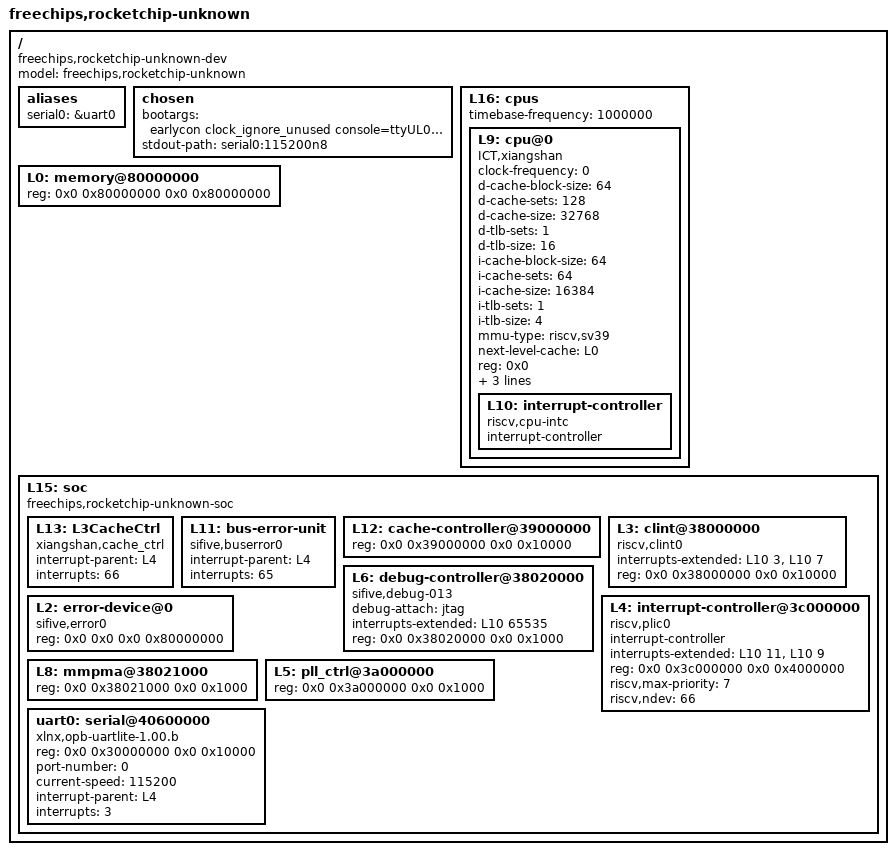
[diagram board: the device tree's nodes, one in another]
/dts-v1/;

/ {
	#address-cells = <2>;
	#size-cells = <2>;
	compatible = "freechips,rocketchip-unknown-dev";
	model = "freechips,rocketchip-unknown";

	aliases {
		serial0 = &uart0;
	};

	chosen {
		bootargs = "earlycon clock_ignore_unused console=ttyUL0,115200n8 root=/dev/mmcblk0p2 rw rootwait";
		stdout-path = "serial0:115200n8";
	};
	
	L16: cpus {
		#address-cells = <1>;
		#size-cells = <0>;
		timebase-frequency = <1000000>;
		L9: cpu@0 {
			clock-frequency = <0>;
			compatible = "ICT,xiangshan", "riscv";
			d-cache-block-size = <64>;
			d-cache-sets = <128>;
			d-cache-size = <32768>;
			d-tlb-sets = <1>;
			d-tlb-size = <16>;
			device_type = "cpu";
			i-cache-block-size = <64>;
			i-cache-sets = <64>;
			i-cache-size = <16384>;
			i-tlb-sets = <1>;
			i-tlb-size = <4>;
			mmu-type = "riscv,sv39";
			next-level-cache = <&L0>;
			reg = <0x0>;
			riscv,isa = "rv64imafdc";
			status = "okay";
			timebase-frequency = <1000000>;
			tlb-split;
			L10: interrupt-controller {
				#interrupt-cells = <1>;
				compatible = "riscv,cpu-intc";
				interrupt-controller;
			};
		};
	};
	L0: memory@80000000 {
		device_type = "memory";
		reg = <0x0 0x80000000 0x0 0x80000000>;
	};
	L15: soc {
		#address-cells = <2>;
		#size-cells = <2>;
		compatible = "freechips,rocketchip-unknown-soc", "simple-bus";
		ranges;
		L13: L3CacheCtrl {
			compatible = "xiangshan,cache_ctrl";
			interrupt-parent = <&L4>;
			interrupts = <66>;
		};
		L11: bus-error-unit {
			compatible = "sifive,buserror0";
			interrupt-parent = <&L4>;
			interrupts = <65>;
		};
		L12: cache-controller@39000000 {
			reg = <0x0 0x39000000 0x0 0x10000>;
			reg-names = "control";
		};
		L3: clint@38000000 {
			compatible = "riscv,clint0";
			interrupts-extended = <&L10 3 &L10 7>;
			reg = <0x0 0x38000000 0x0 0x10000>;
			reg-names = "control";
		};
		L6: debug-controller@38020000 {
			compatible = "sifive,debug-013", "riscv,debug-013";
			debug-attach = "jtag";
			interrupts-extended = <&L10 65535>;
			reg = <0x0 0x38020000 0x0 0x1000>;
			reg-names = "control";
		};
		L2: error-device@0 {
			compatible = "sifive,error0";
			reg = <0x0 0x0 0x0 0x80000000>;
		};
		L4: interrupt-controller@3c000000 {
			#interrupt-cells = <1>;
			compatible = "riscv,plic0";
			interrupt-controller;
			interrupts-extended = <&L10 11 &L10 9>;
			reg = <0x0 0x3c000000 0x0 0x4000000>;
			reg-names = "control";
			riscv,max-priority = <7>;
			riscv,ndev = <66>;
		};
		L8: mmpma@38021000 {
			reg = <0x0 0x38021000 0x0 0x1000>;
			reg-names = "control";
		};
		L5: pll_ctrl@3a000000 {
			reg = <0x0 0x3a000000 0x0 0x1000>;
			reg-names = "control";
		};
		uart0: serial@40600000 {
			compatible = "xlnx,opb-uartlite-1.00.b";
			reg = <0x0 0x30000000 0x0 0x10000>;
			port-number = <0>;
			current-speed = <115200>;
			interrupt-parent = <&L4>;
			interrupts = <3>;
		};
	};
};
